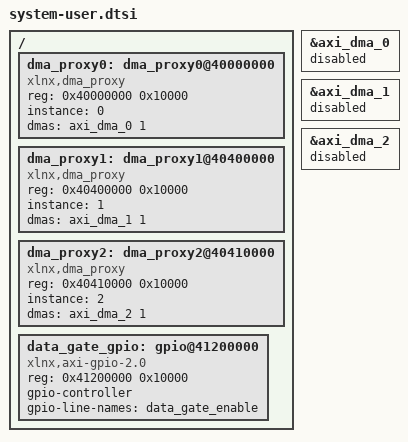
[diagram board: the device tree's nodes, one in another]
/include/ "system-conf.dtsi"

/ {

    dma_proxy0: dma_proxy0@40000000 {
        compatible = "xlnx,dma_proxy";
        reg = <0x40000000 0x10000>;
	instance = <0>;
        dmas = <&axi_dma_0 1>;
        dma-names = "rx0";
        status = "okay";
    };

    dma_proxy1: dma_proxy1@40400000 {
        compatible = "xlnx,dma_proxy";
        reg = <0x40400000 0x10000>;
	instance = <1>;
        dmas = <&axi_dma_1 1>;
        dma-names = "rx1";
        status = "okay";
    };
    dma_proxy2: dma_proxy2@40410000 {
        compatible = "xlnx,dma_proxy";
        reg = <0x40410000 0x10000>;
	instance = <2>;
        dmas = <&axi_dma_2 1>;
        dma-names = "rx2";
        status = "okay";
    };
    data_gate_gpio: gpio@41200000 {
        compatible = "xlnx,axi-gpio-2.0", "xlnx,xps-gpio-1.00.a";
        reg = <0x41200000 0x10000>;
        gpio-controller;
        #gpio-cells = <2>;
        gpio-line-names = "data_gate_enable";
    };
};

/* Disable standalone DMA cores */
&axi_dma_0 { status = "disabled"; };
&axi_dma_1 { status = "disabled"; };
&axi_dma_2 { status = "disabled"; };


